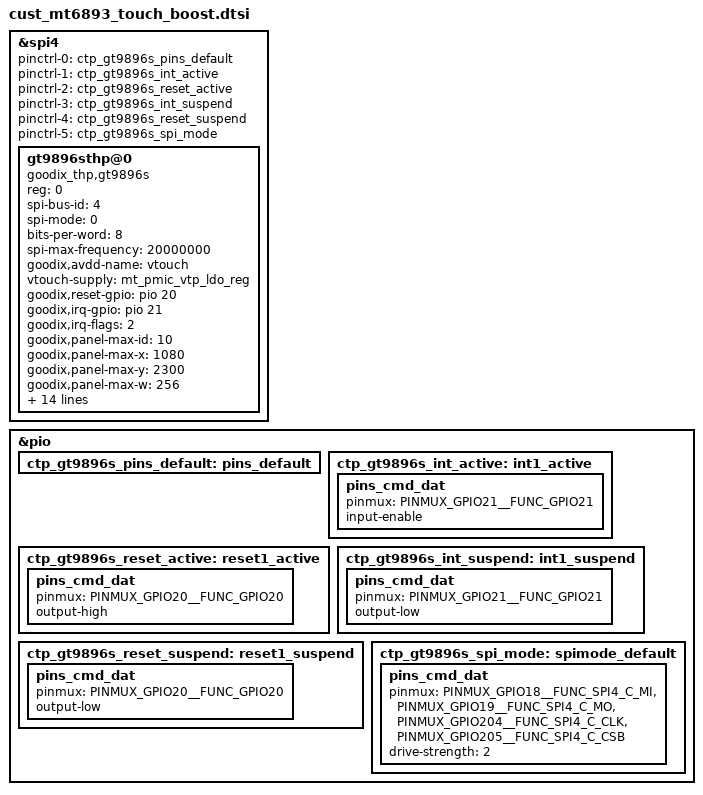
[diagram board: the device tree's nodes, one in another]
/* SPDX-License-Identifier: GPL-2.0 */
/*
 * Copyright (c) 2019 MediaTek Inc.
*/
/* TOUCH start */
&spi4 {
	status = "okay";
	#address-cells = <1>;
	#size-cells = <0>;
	pinctrl-names = "default", "gt9896s_int_active",
		"gt9896s_reset_active", "gt9896s_int_suspend",
		"gt9896s_reset_suspend", "gt9896s_spi_mode";
	pinctrl-0 = <&ctp_gt9896s_pins_default>;
	pinctrl-1 = <&ctp_gt9896s_int_active>;
	pinctrl-2 = <&ctp_gt9896s_reset_active>;
	pinctrl-3 = <&ctp_gt9896s_int_suspend>;
	pinctrl-4 = <&ctp_gt9896s_reset_suspend>;
	pinctrl-5 = <&ctp_gt9896s_spi_mode>;

	gt9896sthp@0 {
		compatible = "goodix_thp,gt9896s";
		reg = <0>; //Same as CS ID
		spi-bus-id = <4>;
		spi-mode = <0>;
		bits-per-word = <8>;
		spi-max-frequency = <20000000>;
		goodix,avdd-name = "vtouch";
		vtouch-supply = <&mt_pmic_vtp_ldo_reg>;
		goodix,reset-gpio = <&pio 20 0x0>;
		goodix,irq-gpio = <&pio 21 0x0>;
		goodix,irq-flags = <2>; /* 1:rising, 2:falling;*/
		goodix,panel-max-id = <10>;
		goodix,panel-max-x = <1080>;
		goodix,panel-max-y = <2300>;
		goodix,panel-max-w = <256>;
		goodix,panel-max-p = <256>;
		goodix,input-max-x = <1080>;
		goodix,input-max-y = <2300>;
		goodix,panel-key-map = <158 172 217>; /*BACK,HOMEPAGE,SEARCH*/
		goodix,power-on-delay-us = <10000>; /*10ms*/
		goodix,power-off-delay-us = <5000>;
		/*goodix,swap-axis;*/
		/*goodix,x2x;*/
		/*goodix,y2y;*/
		goodix,pen-enable;
		tpd-filter-enable = <0>;
		tpd-filter-pixel-density = <161>;
		tpd-filter-custom-prameters = <0 0 0 0 0 0 0 0 0 0 0 0>;
		tpd-filter-custom-speed = <0 0 0>;
		tpd-tll-enable = <1>;
		tpd-tll-para-ver = <1>;
	};
};

&pio {
	ctp_gt9896s_pins_default: pins_default {
	};
	ctp_gt9896s_int_active: int1_active {
		pins_cmd_dat {
			pinmux = <PINMUX_GPIO21__FUNC_GPIO21>;
			input-enable;
		};
	};
	ctp_gt9896s_reset_active: reset1_active {
		pins_cmd_dat {
			pinmux = <PINMUX_GPIO20__FUNC_GPIO20>;
			output-high;
		};
	};
	ctp_gt9896s_int_suspend: int1_suspend {
		pins_cmd_dat {
			pinmux = <PINMUX_GPIO21__FUNC_GPIO21>;
			output-low;
		};
	};
	ctp_gt9896s_reset_suspend: reset1_suspend {
		pins_cmd_dat {
			pinmux = <PINMUX_GPIO20__FUNC_GPIO20>;
			output-low;
		};
	};
	ctp_gt9896s_spi_mode: spimode_default {
		pins_cmd_dat {
			pinmux = <PINMUX_GPIO18__FUNC_SPI4_C_MI>,
				<PINMUX_GPIO19__FUNC_SPI4_C_MO>,
				<PINMUX_GPIO204__FUNC_SPI4_C_CLK>,
				<PINMUX_GPIO205__FUNC_SPI4_C_CSB>;
			drive-strength = <2>;
		};
	};
};
/* TOUCH end */
